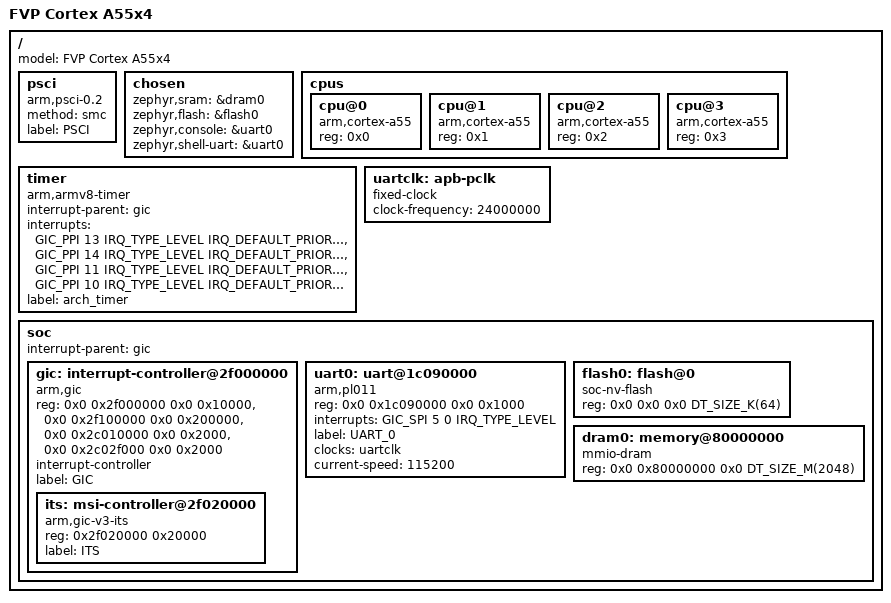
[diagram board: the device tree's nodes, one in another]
/*
 * Copyright (c) 2021 Carlo Caione <ccaione@baylibre.com>
 * SPDX-License-Identifier: Apache-2.0
 */

/dts-v1/;

#include <mem.h>
#include <arm64/armv8-a.dtsi>
#include <dt-bindings/interrupt-controller/arm-gic.h>

/ {
	model = "FVP Cortex A55x4";
	#address-cells = <2>;
	#size-cells = <2>;

	psci {
		compatible = "arm,psci-0.2";
		method = "smc";
		label = "PSCI";
	};

	chosen {
		/*
		 * The SRAM node is actually located in the
		 * DRAM region of the FVP Cortex A55x4.
		 */
		zephyr,sram = &dram0;
		zephyr,flash = &flash0;
		zephyr,console = &uart0;
		zephyr,shell-uart = &uart0;
	};

	cpus {
		#address-cells = <1>;
		#size-cells = <0>;

		cpu@0 {
			device_type = "cpu";
			compatible = "arm,cortex-a55";
			reg = <0x0>;
		};

		cpu@1 {
			device_type = "cpu";
			compatible = "arm,cortex-a55";
			reg = <0x1>;
		};

		cpu@2 {
			device_type = "cpu";
			compatible = "arm,cortex-a55";
			reg = <0x2>;
		};

		cpu@3 {
			device_type = "cpu";
			compatible = "arm,cortex-a55";
			reg = <0x3>;
		};

	};

	timer {
		compatible = "arm,armv8-timer";
		interrupt-parent = <&gic>;
		interrupts = <GIC_PPI 13 IRQ_TYPE_LEVEL
			      IRQ_DEFAULT_PRIORITY>,
			     <GIC_PPI 14 IRQ_TYPE_LEVEL
			      IRQ_DEFAULT_PRIORITY>,
			     <GIC_PPI 11 IRQ_TYPE_LEVEL
			      IRQ_DEFAULT_PRIORITY>,
			     <GIC_PPI 10 IRQ_TYPE_LEVEL
			      IRQ_DEFAULT_PRIORITY>;
		label = "arch_timer";
	};

	uartclk: apb-pclk {
		compatible = "fixed-clock";
		clock-frequency = <24000000>;
		#clock-cells = <0>;
	};

	soc {
		interrupt-parent = <&gic>;

		gic: interrupt-controller@2f000000 {
			#address-cells = <1>;
			#size-cells = <1>;

			compatible = "arm,gic";
			reg = <0x0 0x2f000000 0x0 0x10000>, 	// GICD
			      <0x0 0x2f100000 0x0 0x200000>, 	// GICR
				  <0x0 0x2c010000 0x0 0x2000>, 		// GICC
				  <0x0 0x2c02f000 0x0 0x2000>; 		// GICV
			interrupt-controller;
			#interrupt-cells = <4>;
			/*
			 *It seems that, direct add interrupt for vcpu interface is failed,
			 *Try use the default vcpu interface irq num:25
			*/
			//interrupts = <GIC_PPI 9 IRQ_TYPE_LEVEL IRQ_DEFAULT_PRIORITY>;
			label = "GIC";
			status = "okay";
			#address-cells = <1>;
			#size-cells = <1>;

			its: msi-controller@2f020000 {
				compatible = "arm,gic-v3-its";
				reg = <0x2f020000 0x20000>;
				label = "ITS";
				status = "okay";
			};
		};

		uart0: uart@1c090000 {

			compatible = "arm,pl011";
			reg = <0x0 0x1c090000 0x0 0x1000>;
			status = "disabled";
			/* For uart's gic_spi is 37 = 32(base) + 5(offset) */
			interrupts = <GIC_SPI 5 0 IRQ_TYPE_LEVEL>;
			interrupt-names = "irq_0";
			label = "UART_0";
			clocks = <&uartclk>;
		};

		flash0: flash@0 {

			compatible = "soc-nv-flash";
			reg = <0x0 0x0 0x0 DT_SIZE_K(64)>;
		};

		dram0: memory@80000000 {

			compatible = "mmio-dram";
			reg = <0x0 0x80000000 0x0 DT_SIZE_M(2048)>;
		};

	};

};

&uart0 {
	status = "okay";
	current-speed = <115200>;
};
